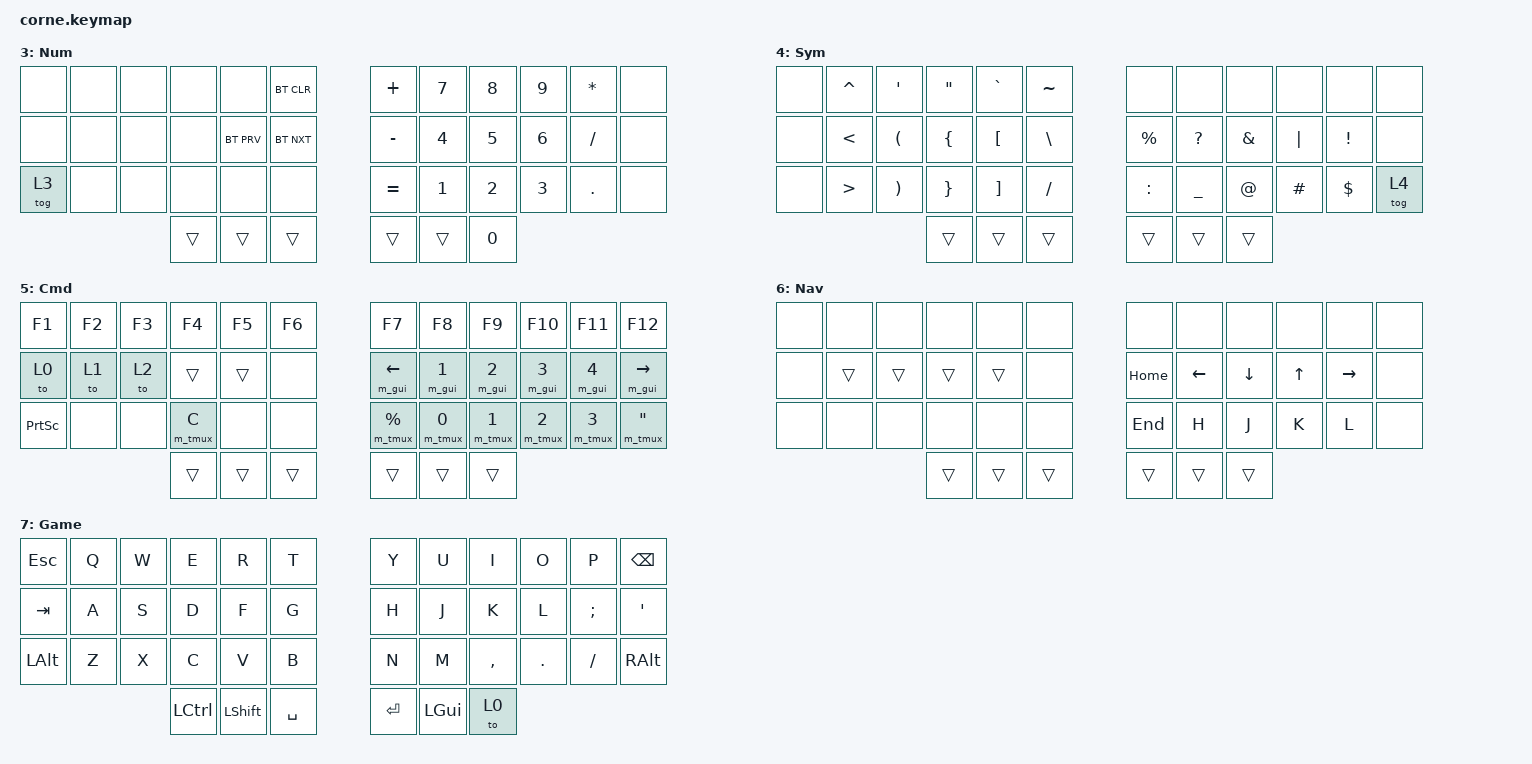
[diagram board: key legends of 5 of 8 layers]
/*
 * Copyright (c) 2020 The ZMK Contributors
 *
 * SPDX-License-Identifier: MIT
 */

#include <behaviors.dtsi>
#include <dt-bindings/zmk/keys.h>
#include <dt-bindings/zmk/bt.h>

#define MEH LC(LS(LALT))
#define HYPER LC(LS(LA(LGUI)))

#define HRML(k1,k2,k3,k4) &hm_l LALT k1   &hm_l LCTRL k2    &hm_l LSHIFT k3    &hm_l LGUI k4
#define HRMR(k1,k2,k3,k4) &hm_r RGUI k1   &hm_r RSHIFT k2   &hm_r RCTRL k3     &hm_r RALT k4
#define HRML_W(k1,k2,k3,k4) &hm_l LGUI k1   &hm_l LCTRL k2    &hm_l LSHIFT k3    &hm_l LALT k4
#define HRMR_W(k1,k2,k3,k4) &hm_r RALT k1   &hm_r RSHIFT k2   &hm_r RCTRL k3     &hm_r RGUI k4
#define HRML_M(k1,k2,k3,k4) &hm_l LALT k1   &hm_l LGUI k2     &hm_l LSHIFT k3    &hm_l LCTRL k4
#define HRMR_M(k1,k2,k3,k4) &hm_r RCTRL k1  &hm_r RSHIFT k2   &hm_r RGUI k3      &hm_r RALT k4

/ {
        macros {
                m_gui: m_gui {
                compatible = "zmk,behavior-macro-one-param";
                #binding-cells = <1>;
                bindings
                        = <&macro_press &kp LGUI>
                        , <&macro_param_1to1>
                        , <&macro_tap &kp MACRO_PLACEHOLDER>
                        , <&macro_release &kp LGUI>
                        ;
                };

                m_tmux: m_tmux {
                compatible = "zmk,behavior-macro-one-param";
                #binding-cells = <1>;
                bindings
                        = <&macro_press &kp LCTRL>
                        , <&macro_tap &kp B>
                        , <&macro_release &kp LCTRL>
                        , <&macro_param_1to1>
                        , <&macro_tap &kp MACRO_PLACEHOLDER>
                        ;
                };

        };

        behaviors {
                hm_l: homerow_mods_left {
                        compatible = "zmk,behavior-hold-tap";
                        label = "HOMEROW_MODS_LEFT";
                        #binding-cells = <2>;
                        tapping-term-ms = <280>;
                        quick-tap-ms = <175>;
                        require-prior-idle-ms = <150>;
                        flavor = "balanced";
                        bindings = <&kp>, <&kp>;
                        hold-trigger-key-positions = <6 7 8 9 10 11 18 19 20 21 22 23 30 31 32 33 34 35 36 37 38 39 40 41>;
                        hold-trigger-on-release;
                };

                hm_r: homerow_mods_right {
                        compatible = "zmk,behavior-hold-tap";
                        label = "HOMEROW_MODS_RIGHT";
                        #binding-cells = <2>;
                        tapping-term-ms = <280>;
                        quick-tap-ms = <175>;
                        require-prior-idle-ms = <150>;
                        flavor = "balanced";
                        bindings = <&kp>, <&kp>;
                        hold-trigger-key-positions = <0 1 2 3 4 5 12 13 14 15 16 17 24 25 26 27 28 29 36 37 38 39 40 41>;
                        hold-trigger-on-release;
                };
        };

        keymap {
                compatible = "zmk,keymap";

                default_layer {
                        label = "Linux";
                        bindings = <
//        ╭───────────┬───────────┬───────────┬───────────┬───────────┬───────────╮     ╭───────────┬───────────┬───────────┬───────────┬───────────┬───────────╮                    
//        │     *     │     Q     │     W     │     F     │     P     │     B     │     │     J     │     L     │     U     │     Y     │     ;     │     *     │
             &kp ESC      &kp Q       &kp W       &kp F       &kp P       &kp B             &kp J       &kp L       &kp U      &kp Y       &kp SEMI    &kp BSPC
//        ├───────────┼───────────┼───────────┼───────────┼───────────┼───────────┤     ├───────────┼───────────┼───────────┼───────────┼───────────┼───────────┤                                                                                                                                                  ────┤
//        │     *     │  A (Alt)  │  R (Ctrl) │ S (Shift) │ T (Super) │     G     │     │     M     │ N (Super) │ E (Shift) │  I (Ctrl) │  O (Alt)  │     *     │                                                                                                                                                  ACE │
           &kt LSHIFT    HRML(A,        R,          S,          T)        &kp G             &kp M      HRMR(N,        E,          I,          O)        &none
//        ├───────────┼───────────┼───────────┼───────────┼───────────┼───────────┤     ├───────────┼───────────┼───────────┼───────────┼───────────┼───────────┤                                                                                                                                                  ────┤
//        │     *     │     Z     │     X     │     C     │     D     │     V     │     │     K     │     H     │     ,     │     .     │     /     │     *     │                                                                                                                                                  ACE │
              &tog 3      &kp Z       &kp X       &kp C       &kp D       &kp V             &kp K       &kp H     &kp COMMA    &kp DOT    &kp FSLH     &tog 4
//        ╰───────────┼───────────┼───────────┼───────────┼───────────┼───────────┤     ├───────────┼───────────┼───────────┼───────────┼───────────┼───────────╯  
                                                 &kp MEH    &lt 3 TAB  &lt 6 SPACE        &lt 5 RET   &lt 4 BSPC  &kp HYPER
//                                            ╰───────────┴───────────┴───────────╯     ╰───────────┴───────────┴───────────╯
                        >;
                };

                windows_layer {
                        label = "Win";
                        bindings = <
//        ╭───────────┬───────────┬───────────┬───────────┬───────────┬───────────╮     ╭───────────┬───────────┬───────────┬───────────┬───────────┬───────────╮                    
             &kp ESC      &kp Q       &kp W       &kp F       &kp P       &kp B             &kp J       &kp L       &kp U      &kp Y       &kp SEMI    &kp BSPC
//        ├───────────┼───────────┼───────────┼───────────┼───────────┼───────────┤     ├───────────┼───────────┼───────────┼───────────┼───────────┼───────────┤
           &kt LSHIFT   HRML_W(A,       R,          S,          T)        &kp G             &kp M     HRMR_W(N,       E,          I,          O)        &to 7
//        ├───────────┼───────────┼───────────┼───────────┼───────────┼───────────┤     ├───────────┼───────────┼───────────┼───────────┼───────────┼───────────┤
              &tog 3      &kp Z       &kp X       &kp C       &kp D       &kp V              &kp K      &kp H     &kp COMMA    &kp DOT    &kp FSLH     &tog 4
//        ╰───────────┼───────────┼───────────┼───────────┼───────────┼───────────┤     ├───────────┼───────────┼───────────┼───────────┼───────────┼───────────╯  
                                                 &kp MEH    &lt 3 TAB  &lt 6 SPACE        &lt 5 RET   &lt 4 BSPC  &kp HYPER
//                                            ╰───────────┴───────────┴───────────╯     ╰───────────┴───────────┴───────────╯
                        >;
                };

                mac_layer {
                        label = "Mac";
                        bindings = <
//        ╭───────────┬───────────┬───────────┬───────────┬───────────┬───────────╮     ╭───────────┬───────────┬───────────┬───────────┬───────────┬───────────╮                    
             &kp ESC      &kp Q       &kp W       &kp F       &kp P       &kp B             &kp J       &kp L       &kp U      &kp Y       &kp SEMI    &kp BSPC
//        ├───────────┼───────────┼───────────┼───────────┼───────────┼───────────┤     ├───────────┼───────────┼───────────┼───────────┼───────────┼───────────┤
           &kt LSHIFT   HRML_M(A,       R,          S,          T)        &kp G             &kp M     HRMR_M(N,       E,          I,          O)        &to 7
//        ├───────────┼───────────┼───────────┼───────────┼───────────┼───────────┤     ├───────────┼───────────┼───────────┼───────────┼───────────┼───────────┤
              &tog 3      &kp Z       &kp X       &kp C       &kp D       &kp V              &kp K      &kp H      &kp COMMA    &kp DOT    &kp FSLH     &tog 4
//        ╰───────────┼───────────┼───────────┼───────────┼───────────┼───────────┤     ├───────────┼───────────┼───────────┼───────────┼───────────┼───────────╯  
                                                 &kp MEH    &lt 3 TAB  &lt 6 SPACE        &lt 5 RET   &lt 4 BSPC  &kp HYPER
//                                            ╰───────────┴───────────┴───────────╯     ╰───────────┴───────────┴───────────╯
                        >;
                };

                num_layer {
                        label = "Num";
                        bindings = <
//        ╭───────────┬───────────┬───────────┬───────────┬───────────┬───────────╮     ╭───────────┬───────────┬───────────┬───────────┬───────────┬───────────╮                    
//        │     *     │     *     │     *     │     *     │     *     │     *     │     │     +     │     7     │     8     │     9     │     *     │     *     │
              &none       &none      &none       &none       &none      &bt BT_CLR        &kp PLUS     &kp N7      &kp N8      &kp N9      &kp STAR     &none
//        ├───────────┼───────────┼───────────┼───────────┼───────────┼───────────┤     ├───────────┼───────────┼───────────┼───────────┼───────────┼───────────┤                                                                                                                                                  ────┤
//        │     *     │     *     │     *     │     *     │     *     │     *     │     │     -     │     4     │     5     │     6     │     /     │     *     │                                                                                                                                                  ACE │
              &none       &none       &none      &none     &bt BT_PRV   &bt BT_NXT        &kp MINUS    &kp N4      &kp N5      &kp N6      &kp FSLH     &none
//        ├───────────┼───────────┼───────────┼───────────┼───────────┼───────────┤     ├───────────┼───────────┼───────────┼───────────┼───────────┼───────────┤                                                                                                                                                  ────┤
//        │     *     │     *     │     *     │     *     │     *     │     *     │     │     =     │     1     │     2     │     3     │     .     │     *     │                                                                                                                                                  ACE │
              &tog 3      &none      &none       &none        &none       &none           &kp EQUAL    &kp N1      &kp N2      &kp N3      &kp DOT      &none
//        ╰───────────┼───────────┼───────────┼───────────┼───────────┼───────────┤     ├───────────┼───────────┼───────────┼───────────┼───────────┼───────────╯  
                                                  &trans     &trans       &trans           &trans      &trans      &kp N0
//                                            ╰───────────┴───────────┴───────────╯     ╰───────────┴───────────┴───────────╯
                        >;
                };

                sym_layer {
                        label = "Sym";
                        bindings = <
//        ╭───────────┬───────────┬───────────┬───────────┬───────────┬───────────╮     ╭───────────┬───────────┬───────────┬───────────┬───────────┬───────────╮                    
//        │     *     │     ^     │     '     │     "     │     `     │     ~     │     │     *     │     *     │     *     │     *     │     *     │     *     │
              &none     &kp CARET    &kp SQT     &kp DQT    &kp GRAVE   &kp TILDE           &none       &none       &none       &none       &none       &none
//        ├───────────┼───────────┼───────────┼───────────┼───────────┼───────────┤     ├───────────┼───────────┼───────────┼───────────┼───────────┼───────────┤                                                                                                                                                  ────┤
//        │     *     │     <     │     (     │     {     │     [     │     \     │     │     %     │     ?     │     &     │     |     │     !     │     *     │                                                                                                                                                  ACE │
              &none       &kp LT     &kp LPAR    &kp LBRC    &kp LBKT    &kp BSLH         &kp PRCNT   &kp QMARK    &kp AMPS    &kp PIPE    &kp EXCL     &none
//        ├───────────┼───────────┼───────────┼───────────┼───────────┼───────────┤     ├───────────┼───────────┼───────────┼───────────┼───────────┼───────────┤                                                                                                                                                  ────┤
//        │     *     │     >     │     )     │     }     │     ]     │     /     │     │     :     │     _     │     @     │     #     │     $     │     *     │                                                                                                                                                  ACE │
              &none       &kp GT     &kp RPAR    &kp RBRC    &kp RBKT    &kp FSLH         &kp COLON   &kp UNDER     &kp AT     &kp HASH    &kp DLLR     &tog 4
//        ╰───────────┼───────────┼───────────┼───────────┼───────────┼───────────┤     ├───────────┼───────────┼───────────┼───────────┼───────────┼───────────╯  
                                                  &trans     &trans       &trans           &trans      &trans       &trans
//                                            ╰───────────┴───────────┴───────────╯     ╰───────────┴───────────┴───────────╯
                        >;
                };

                cmd_layer {
                        label = "Cmd";
                        bindings = <
//        ╭───────────┬───────────┬───────────┬───────────┬───────────┬───────────╮     ╭───────────┬───────────┬───────────┬───────────┬───────────┬───────────╮                    
//        │     *     │     *     │     *     │     *     │     *     │     *     │     │     *     │     *     │     *     │     *     │     *     │     *     │
              &kp F1     &kp F2       &kp F3      &kp F4      &kp F5      &kp F6            &kp F7     &kp F8       &kp F9     &kp F10     &kp F11     &kp F12
//        ├───────────┼───────────┼───────────┼───────────┼───────────┼───────────┤     ├───────────┼───────────┼───────────┼───────────┼───────────┼───────────┤                                                                                                                                                  ────┤
//        │     *     │     *     │     *     │     *     │     *     │     *     │     │     *     │     *     │     *     │     *     │     *     │     *     │                                                                                                                                                  ACE │
              &to 0       &to 1     &to 2      &trans       &trans      &none          &m_gui LEFT  &m_gui N1   &m_gui N2   &m_gui N3   &m_gui N4  &m_gui RIGHT
//        ├───────────┼───────────┼───────────┼───────────┼───────────┼───────────┤     ├───────────┼───────────┼───────────┼───────────┼───────────┼───────────┤                                                                                                                                                  ────┤
//        │     *     │     *     │     *     │     *     │     *     │     *     │     │     *     │     H     │     J     │     K     │     L     │     *     │                                                                                                                                                  ACE │
              &kp PSCRN   &none      &none      &m_tmux C     &none       &none         &m_tmux PRCNT &m_tmux N0  &m_tmux N1  &m_tmux N2  &m_tmux N3  &m_tmux DQT
//        ╰───────────┼───────────┼───────────┼───────────┼───────────┼───────────┤     ├───────────┼───────────┼───────────┼───────────┼───────────┼───────────╯  
                                                  &trans     &trans       &trans           &trans      &trans       &trans
//                                            ╰───────────┴───────────┴───────────╯     ╰───────────┴───────────┴───────────╯
                        >;
                };

                nav_layer {
                        label = "Nav";
                        bindings = <
//        ╭───────────┬───────────┬───────────┬───────────┬───────────┬───────────╮     ╭───────────┬───────────┬───────────┬───────────┬───────────┬───────────╮                    
//        │     *     │     *     │     *     │     *     │     *     │     *     │     │     *     │     *     │     *     │     *     │     *     │     *     │
              &none       &none      &none       &none       &none        &none             &none       &none       &none       &none       &none       &none
//        ├───────────┼───────────┼───────────┼───────────┼───────────┼───────────┤     ├───────────┼───────────┼───────────┼───────────┼───────────┼───────────┤                                                                                                                                                  ────┤
//        │     *     │     *     │     *     │     *     │     *     │     *     │     │     *     │     *     │     *     │     *     │     *     │     *     │                                                                                                                                                  ACE │
              &none       &trans     &trans      &trans       &trans      &none            &kp HOME   &kp LEFT    &kp DOWN     &kp UP     &kp RIGHT     &none
//        ├───────────┼───────────┼───────────┼───────────┼───────────┼───────────┤     ├───────────┼───────────┼───────────┼───────────┼───────────┼───────────┤                                                                                                                                                  ────┤
//        │     *     │     *     │     *     │     *     │     *     │     *     │     │     *     │     H     │     J     │     K     │     L     │     *     │                                                                                                                                                  ACE │
              &none       &none      &none       &none        &none       &none            &kp END      &kp H       &kp J       &kp K       &kp L       &none
//        ╰───────────┼───────────┼───────────┼───────────┼───────────┼───────────┤     ├───────────┼───────────┼───────────┼───────────┼───────────┼───────────╯  
                                                  &trans     &trans       &trans           &trans      &trans       &trans
//                                            ╰───────────┴───────────┴───────────╯     ╰───────────┴───────────┴───────────╯
                        >;
                };

                                
                game_layer {
                        label = "Game";
                        bindings = <
                                &kp ESC   &kp Q &kp W &kp E &kp R &kp T   &kp Y &kp U  &kp I     &kp O   &kp P    &kp BSPC
                                &kp TAB   &kp A &kp S &kp D &kp F &kp G   &kp H &kp J  &kp K     &kp L   &kp SEMI &kp SQT
                                &kp LALT  &kp Z &kp X &kp C &kp V &kp B   &kp N &kp M  &kp COMMA &kp DOT &kp FSLH &kp RALT
                                         &kp LCTRL &kp LSHIFT &kp SPACE   &kp RET &kp LGUI &to 0
                        >;
                };
        };        
};
